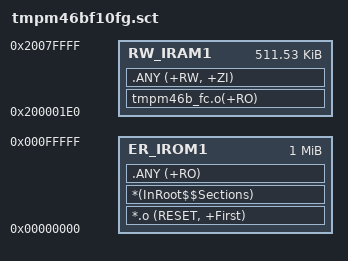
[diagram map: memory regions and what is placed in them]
#! armcc -E -I. --cpu Cortex-M4
;;  TMPM46BF10 scatter file

;;  Vector table starts at 0
;;    Initial SP == |Image$$ARM_LIB_STACK$$ZI$$Limit| (for two region model)
;;               or |Image$$ARM_LIB_STACKHEAP$$ZI$$Limit| (for one region model)
;;    Initial PC == &__main (with LSB set to indicate Thumb)
;;    These two values are provided by the library
;;    Other vectors must be provided by the user
;;  Code starts after the last possible vector
;;  Data starts at 0x20000000
;;    Heap is positioned by ARM_LIB_HEAB (this is the heap managed by the ARM libraries)
;;    Stack is positioned by ARM_LIB_STACK (library will use this to set SP - see above)

;; Compatible with ISSM model

#if !defined(MBED_APP_START)
  #define MBED_APP_START 0x00000000
#endif

#if !defined(MBED_APP_SIZE)
  #define MBED_APP_SIZE 0x100000
#endif

; TMPM46B: 1024 KB FLASH (0x100000) + 512 KB SRAM (0x80000)

LR_IROM1 MBED_APP_START MBED_APP_SIZE ; load region size_region
{
  ER_IROM1 MBED_APP_START MBED_APP_SIZE
  {
   *.o (RESET, +First)
   *(InRoot$$Sections)
   .ANY (+RO)
  }

  RW_IRAM1 0x200001E0 (0x80000 - 0x1E0)
  {
     tmpm46b_fc.o(+RO)
    .ANY (+RW, +ZI)
  }
}
